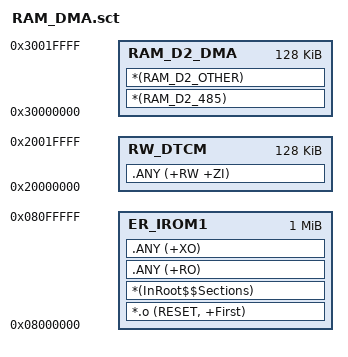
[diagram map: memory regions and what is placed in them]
LR_IROM1 0x08000000 0x00100000
{
    ER_IROM1 0x08000000 0x00100000
    {
        *.o (RESET, +First)
        *(InRoot$$Sections)
        .ANY (+RO)
        .ANY (+XO)
    }

    ;---------------------------------------------------------
    ; DTCM SRAM 128KB —— 全部运行变量 + 栈
    ;---------------------------------------------------------
    RW_DTCM 0x20000000 0x00020000
    {
        .ANY (+RW +ZI)
    }

    ;---------------------------------------------------------
    ; D2 SRAM —— 所有 DMA 专用 128KB
    ;---------------------------------------------------------
    RAM_D2_DMA 0x30000000 0x00020000
    {
        *(RAM_D2_485)
        *(RAM_D2_OTHER)
    }
}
